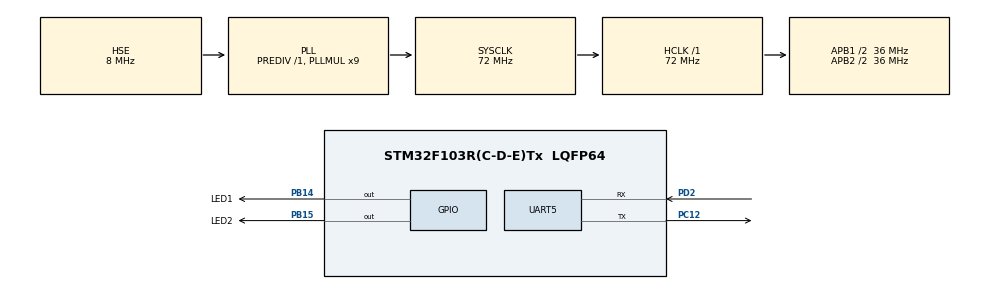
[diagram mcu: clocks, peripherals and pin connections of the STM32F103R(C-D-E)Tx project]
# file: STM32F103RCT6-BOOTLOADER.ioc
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Mcu.Family=STM32F1
Mcu.Name=STM32F103R(C-D-E)Tx
Mcu.Package=LQFP64
NVIC.PriorityGroup=NVIC_PRIORITYGROUP_4
PA13.Mode=Serial_Wire
PA13.Signal=SYS_JTMS-SWDIO
PA14.Mode=Serial_Wire
PA14.Signal=SYS_JTCK-SWCLK
PB14.GPIO_Label=LED1
PB14.Signal=GPIO_Output
PB15.GPIO_Label=LED2
PB15.Signal=GPIO_Output
PC12.Mode=Asynchronous
PC12.Signal=UART5_TX
PD0-OSC_IN.Mode=HSE-External-Oscillator
PD0-OSC_IN.Signal=RCC_OSC_IN
PD1-OSC_OUT.Mode=HSE-External-Oscillator
PD1-OSC_OUT.Signal=RCC_OSC_OUT
PD2.Mode=Asynchronous
PD2.Signal=UART5_RX
ProjectManager.HeapSize=0x400
ProjectManager.StackSize=0x400
ProjectManager.TargetToolchain=EWARM V8.32
RCC.AHBFreq_Value=72000000
RCC.APB1CLKDivider=RCC_HCLK_DIV2
RCC.APB1Freq_Value=36000000
RCC.APB1TimFreq_Value=72000000
RCC.APB2CLKDivider=RCC_HCLK_DIV2
RCC.APB2Freq_Value=36000000
RCC.APB2TimFreq_Value=72000000
RCC.HCLKFreq_Value=72000000
RCC.PLLMUL=RCC_PLL_MUL9
RCC.PLLSourceVirtual=RCC_PLLSOURCE_HSE
RCC.SYSCLKFreq_VALUE=72000000
RCC.SYSCLKSource=RCC_SYSCLKSOURCE_PLLCLK
RCC.USBFreq_Value=48000000
RCC.USBPrescaler=RCC_USBCLKSOURCE_PLL_DIV1_5
UART5.VirtualMode=Asynchronous
board=custom

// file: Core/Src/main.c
/* USER CODE BEGIN Header */
/**
  ******************************************************************************
  * @file           : main.c
  * @brief          : Main program body
  ******************************************************************************
  * @attention
  *
  * <h2><center>&copy; Copyright (c) 2021 STMicroelectronics.
  * All rights reserved.</center></h2>
  *
  * This software component is licensed by ST under Ultimate Liberty license
  * SLA0044, the "License"; You may not use this file except in compliance with
  * the License. You may obtain a copy of the License at:
  *                             www.st.com/SLA0044
  *
  ******************************************************************************
  */
/* USER CODE END Header */
#include "main.h"

/* USER CODE BEGIN Includes */
#include "bootloader.h"
/* USER CODE END Includes */

/* USER CODE BEGIN PTD */
FLASH_EraseInitTypeDef Upgrade_Flash;
/* USER CODE END PTD */

UART_HandleTypeDef huart5;

void SystemClock_Config(void);
static void MX_GPIO_Init(void);
static void MX_UART5_Init(void);

int main(void)
{

  /* MCU Configuration--------------------------------------------------------*/

  /* Reset of all peripherals, Initializes the Flash interface and the Systick. */
  HAL_Init();

  /* Configure the system clock */
  SystemClock_Config();

  /* Initialize all configured peripherals */
  MX_GPIO_Init();
  MX_UART5_Init();
  /* USER CODE BEGIN 2 */
  for(int i = 0;i < 20;i++)
  {
    HAL_GPIO_TogglePin(GPIOB, LED1_Pin);
    HAL_Delay(100);
  }
  /* USER CODE END 2 */

  /* Infinite loop */
  /* USER CODE BEGIN WHILE */
  //while (1)
  {
    /* USER CODE END WHILE */

    /* USER CODE BEGIN 3 */
    HAL_Delay(1000);
    Start_BootLoader();
  }
  /* USER CODE END 3 */
}

void SystemClock_Config(void)
{
  RCC_OscInitTypeDef RCC_OscInitStruct = {0};
  RCC_ClkInitTypeDef RCC_ClkInitStruct = {0};

  /** Initializes the RCC Oscillators according to the specified parameters
  * in the RCC_OscInitTypeDef structure.
  */
  RCC_OscInitStruct.OscillatorType = RCC_OSCILLATORTYPE_HSE;
  RCC_OscInitStruct.HSEState = RCC_HSE_ON;
  RCC_OscInitStruct.HSEPredivValue = RCC_HSE_PREDIV_DIV1;
  RCC_OscInitStruct.HSIState = RCC_HSI_ON;
  RCC_OscInitStruct.PLL.PLLState = RCC_PLL_ON;
  RCC_OscInitStruct.PLL.PLLSource = RCC_PLLSOURCE_HSE;
  RCC_OscInitStruct.PLL.PLLMUL = RCC_PLL_MUL9;
  if (HAL_RCC_OscConfig(&RCC_OscInitStruct) != HAL_OK)
  {
    Error_Handler();
  }
  /** Initializes the CPU, AHB and APB buses clocks
  */
  RCC_ClkInitStruct.ClockType = RCC_CLOCKTYPE_HCLK|RCC_CLOCKTYPE_SYSCLK
                              |RCC_CLOCKTYPE_PCLK1|RCC_CLOCKTYPE_PCLK2;
  RCC_ClkInitStruct.SYSCLKSource = RCC_SYSCLKSOURCE_PLLCLK;
  RCC_ClkInitStruct.AHBCLKDivider = RCC_SYSCLK_DIV1;
  RCC_ClkInitStruct.APB1CLKDivider = RCC_HCLK_DIV2;
  RCC_ClkInitStruct.APB2CLKDivider = RCC_HCLK_DIV2;

  if (HAL_RCC_ClockConfig(&RCC_ClkInitStruct, FLASH_LATENCY_2) != HAL_OK)
  {
    Error_Handler();
  }
}

static void MX_UART5_Init(void)
{

  huart5.Instance = UART5;
  huart5.Init.BaudRate = 115200;
  huart5.Init.WordLength = UART_WORDLENGTH_8B;
  huart5.Init.StopBits = UART_STOPBITS_1;
  huart5.Init.Parity = UART_PARITY_NONE;
  huart5.Init.Mode = UART_MODE_TX_RX;
  huart5.Init.HwFlowCtl = UART_HWCONTROL_NONE;
  huart5.Init.OverSampling = UART_OVERSAMPLING_16;
  if (HAL_UART_Init(&huart5) != HAL_OK)
  {
    Error_Handler();
  }

}

static void MX_GPIO_Init(void)
{
  GPIO_InitTypeDef GPIO_InitStruct = {0};

  /* GPIO Ports Clock Enable */
  __HAL_RCC_GPIOD_CLK_ENABLE();
  __HAL_RCC_GPIOB_CLK_ENABLE();
  __HAL_RCC_GPIOA_CLK_ENABLE();
  __HAL_RCC_GPIOC_CLK_ENABLE();

  /*Configure GPIO pin Output Level */
  HAL_GPIO_WritePin(GPIOB, LED1_Pin|LED2_Pin, GPIO_PIN_RESET);

  /*Configure GPIO pins : LED1_Pin LED2_Pin */
  GPIO_InitStruct.Pin = LED1_Pin|LED2_Pin;
  GPIO_InitStruct.Mode = GPIO_MODE_OUTPUT_PP;
  GPIO_InitStruct.Pull = GPIO_NOPULL;
  GPIO_InitStruct.Speed = GPIO_SPEED_FREQ_LOW;
  HAL_GPIO_Init(GPIOB, &GPIO_InitStruct);

}

void Error_Handler(void)
{
  __disable_irq();
  while (1)
  {
  }
}

/************************ (C) COPYRIGHT STMicroelectronics *****END OF FILE****/
